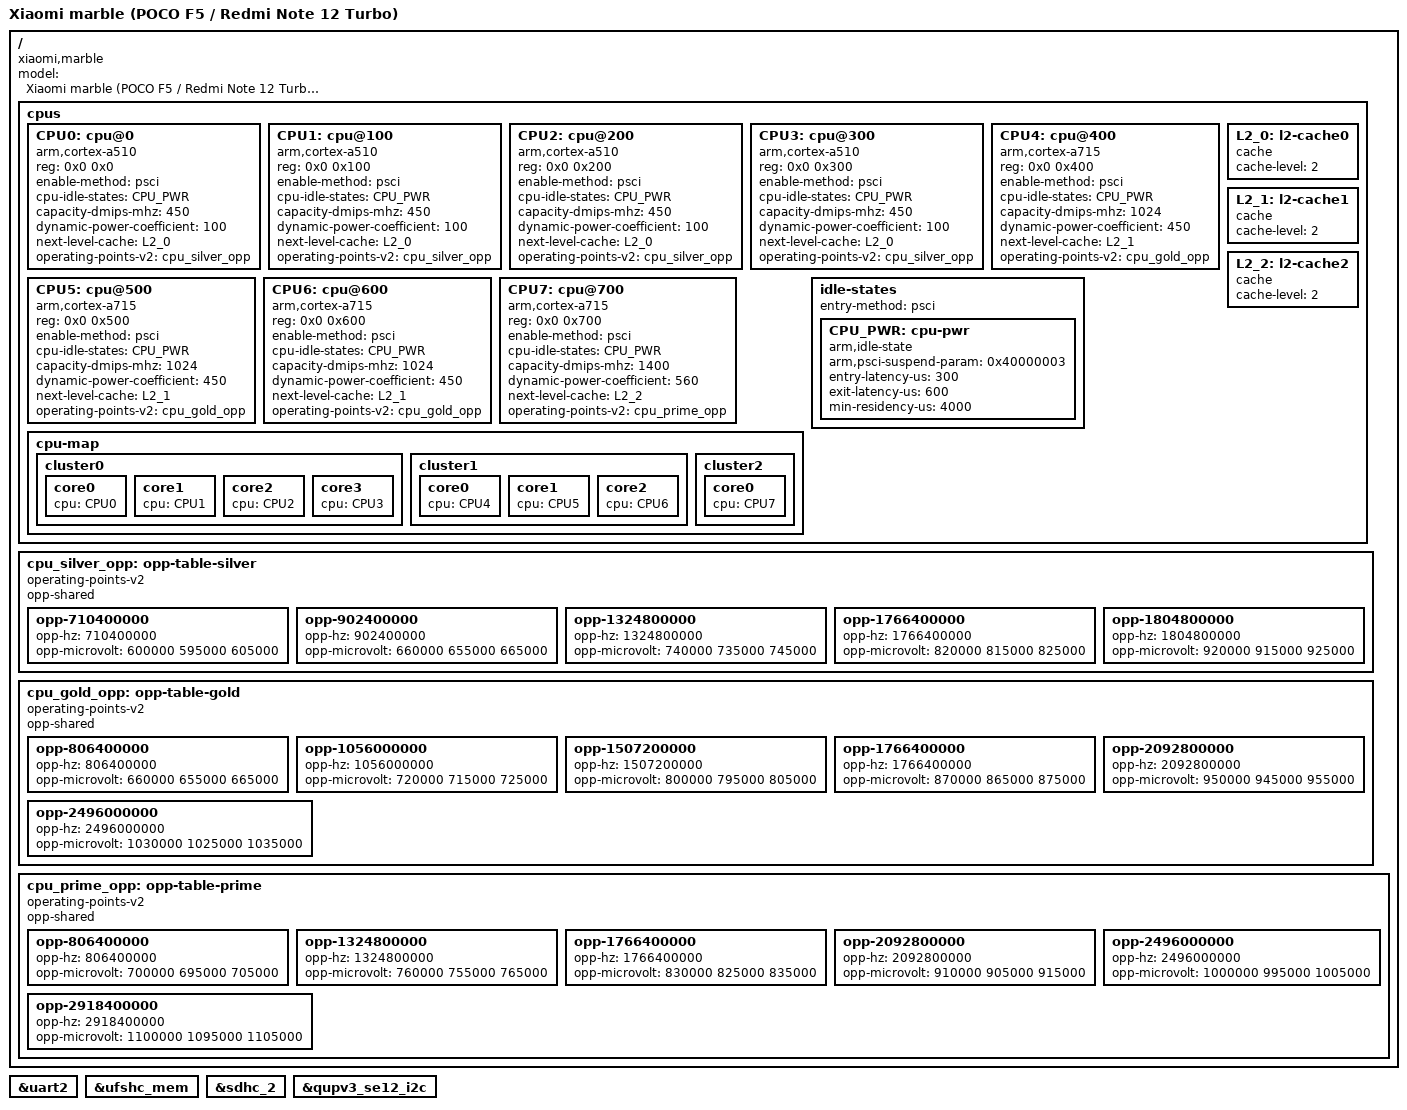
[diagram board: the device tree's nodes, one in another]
// SPDX-License-Identifier: GPL-2.0-only
/*
 * marble-board.dts
 *
 * Top-level board file for Xiaomi marble (POCO F5 / Redmi Note 12 Turbo).
 * Platform: SM8450 (waipio/taro) base, SM7475 (diwali) die.
 *
 * The kernel builds with CONFIG_ARCH_WAIPIO=y and diwali clock overrides.
 * The defconfig chain is: gki_defconfig + waipio_GKI.config +
 * xiaomi_GKI.config + marble_GKI.config.
 *
 * Aurora-Kernel  ::  ACK 6.18 LTS
 */

/dts-v1/;

#include "waipio.dtsi"
#include "sm7475-marble.dtsi"
#include "marble-peripherals.dtsi"

/ {
    model = "Xiaomi marble (POCO F5 / Redmi Note 12 Turbo)";
    compatible = "xiaomi,marble", "qcom,waipio", "qcom,diwali";

    /*
     * CPU cluster topology for EAS.
     * SM7475 = 1x Cortex-A715 prime @ 2.91GHz
     *        + 3x Cortex-A715 gold  @ 2.49GHz
     *        + 4x Cortex-A510 silver @ 1.80GHz
     */
    cpus {
        #address-cells = <2>;
        #size-cells = <0>;

        CPU0: cpu@0 {
            device_type = "cpu";
            compatible = "arm,cortex-a510";
            reg = <0x0 0x0>;
            enable-method = "psci";
            cpu-idle-states = <&CPU_PWR>;
            capacity-dmips-mhz = <450>;
            dynamic-power-coefficient = <100>;
            next-level-cache = <&L2_0>;
            operating-points-v2 = <&cpu_silver_opp>;
            #cooling-cells = <2>;
        };

        CPU1: cpu@100 {
            device_type = "cpu";
            compatible = "arm,cortex-a510";
            reg = <0x0 0x100>;
            enable-method = "psci";
            cpu-idle-states = <&CPU_PWR>;
            capacity-dmips-mhz = <450>;
            dynamic-power-coefficient = <100>;
            next-level-cache = <&L2_0>;
            operating-points-v2 = <&cpu_silver_opp>;
        };

        CPU2: cpu@200 {
            device_type = "cpu";
            compatible = "arm,cortex-a510";
            reg = <0x0 0x200>;
            enable-method = "psci";
            cpu-idle-states = <&CPU_PWR>;
            capacity-dmips-mhz = <450>;
            dynamic-power-coefficient = <100>;
            next-level-cache = <&L2_0>;
            operating-points-v2 = <&cpu_silver_opp>;
        };

        CPU3: cpu@300 {
            device_type = "cpu";
            compatible = "arm,cortex-a510";
            reg = <0x0 0x300>;
            enable-method = "psci";
            cpu-idle-states = <&CPU_PWR>;
            capacity-dmips-mhz = <450>;
            dynamic-power-coefficient = <100>;
            next-level-cache = <&L2_0>;
            operating-points-v2 = <&cpu_silver_opp>;
        };

        CPU4: cpu@400 {
            device_type = "cpu";
            compatible = "arm,cortex-a715";
            reg = <0x0 0x400>;
            enable-method = "psci";
            cpu-idle-states = <&CPU_PWR>;
            capacity-dmips-mhz = <1024>;
            dynamic-power-coefficient = <450>;
            next-level-cache = <&L2_1>;
            operating-points-v2 = <&cpu_gold_opp>;
            #cooling-cells = <2>;
        };

        CPU5: cpu@500 {
            device_type = "cpu";
            compatible = "arm,cortex-a715";
            reg = <0x0 0x500>;
            enable-method = "psci";
            cpu-idle-states = <&CPU_PWR>;
            capacity-dmips-mhz = <1024>;
            dynamic-power-coefficient = <450>;
            next-level-cache = <&L2_1>;
            operating-points-v2 = <&cpu_gold_opp>;
        };

        CPU6: cpu@600 {
            device_type = "cpu";
            compatible = "arm,cortex-a715";
            reg = <0x0 0x600>;
            enable-method = "psci";
            cpu-idle-states = <&CPU_PWR>;
            capacity-dmips-mhz = <1024>;
            dynamic-power-coefficient = <450>;
            next-level-cache = <&L2_1>;
            operating-points-v2 = <&cpu_gold_opp>;
        };

        CPU7: cpu@700 {
            device_type = "cpu";
            compatible = "arm,cortex-a715";
            reg = <0x0 0x700>;
            enable-method = "psci";
            cpu-idle-states = <&CPU_PWR>;
            capacity-dmips-mhz = <1400>;
            dynamic-power-coefficient = <560>;
            next-level-cache = <&L2_2>;
            operating-points-v2 = <&cpu_prime_opp>;
            #cooling-cells = <2>;
        };

        /* cluster topology for EAS */
        cpu-map {
            cluster0 {
                core0 { cpu = <&CPU0>; };
                core1 { cpu = <&CPU1>; };
                core2 { cpu = <&CPU2>; };
                core3 { cpu = <&CPU3>; };
            };
            cluster1 {
                core0 { cpu = <&CPU4>; };
                core1 { cpu = <&CPU5>; };
                core2 { cpu = <&CPU6>; };
            };
            cluster2 {
                core0 { cpu = <&CPU7>; };
            };
        };

        idle-states {
            entry-method = "psci";
            CPU_PWR: cpu-pwr {
                compatible = "arm,idle-state";
                arm,psci-suspend-param = <0x40000003>;
                entry-latency-us = <300>;
                exit-latency-us = <600>;
                min-residency-us = <4000>;
            };
        };

        L2_0: l2-cache0 { compatible = "cache"; cache-level = <2>; };
        L2_1: l2-cache1 { compatible = "cache"; cache-level = <2>; };
        L2_2: l2-cache2 { compatible = "cache"; cache-level = <2>; };
    };

    /*
     * OPP tables with Undervolting (UV).
     *
     * UV is achieved via `opp-microvolt = <target min max>`.
     * Values below are conservative (≈ -25mV below stock SM7475).
     * Every device's silicon is different — if you get crashes at high
     * freq, RAISE the target voltage by 10mV increments until stable.
     *
     * Format: opp-microvolt = <target_uv  min_uv  max_uv>;
     *   target_uv = the voltage to actually apply (this is the UV)
     *   min/max   = the regulator tolerance window (keep ±5mV)
     *
     * Stock SM7475 reference voltages (Qualcomm LA.VENDOR.1.0):
     *   silver  : 0.60 - 0.95 V
     *   gold    : 0.65 - 1.05 V
     *   prime   : 0.70 - 1.12 V
     */
    cpu_silver_opp: opp-table-silver {
        compatible = "operating-points-v2";
        opp-shared;

        opp-710400000  { opp-hz = /bits/ 64 <710400000>;
                         opp-microvolt = <600000 595000 605000>; };
        opp-902400000  { opp-hz = /bits/ 64 <902400000>;
                         opp-microvolt = <660000 655000 665000>; };
        opp-1324800000 { opp-hz = /bits/ 64 <1324800000>;
                         opp-microvolt = <740000 735000 745000>; };
        opp-1766400000 { opp-hz = /bits/ 64 <1766400000>;
                         opp-microvolt = <820000 815000 825000>; };
        opp-1804800000 { opp-hz = /bits/ 64 <1804800000>;
                         opp-microvolt = <920000 915000 925000>; };
    };

    cpu_gold_opp: opp-table-gold {
        compatible = "operating-points-v2";
        opp-shared;

        opp-806400000  { opp-hz = /bits/ 64 <806400000>;
                         opp-microvolt = <660000 655000 665000>; };
        opp-1056000000 { opp-hz = /bits/ 64 <1056000000>;
                         opp-microvolt = <720000 715000 725000>; };
        opp-1507200000 { opp-hz = /bits/ 64 <1507200000>;
                         opp-microvolt = <800000 795000 805000>; };
        opp-1766400000 { opp-hz = /bits/ 64 <1766400000>;
                         opp-microvolt = <870000 865000 875000>; };
        opp-2092800000 { opp-hz = /bits/ 64 <2092800000>;
                         opp-microvolt = <950000 945000 955000>; };
        opp-2496000000 { opp-hz = /bits/ 64 <2496000000>;
                         opp-microvolt = <1030000 1025000 1035000>; };
    };

    cpu_prime_opp: opp-table-prime {
        compatible = "operating-points-v2";
        opp-shared;

        opp-806400000  { opp-hz = /bits/ 64 <806400000>;
                         opp-microvolt = <700000 695000 705000>; };
        opp-1324800000 { opp-hz = /bits/ 64 <1324800000>;
                         opp-microvolt = <760000 755000 765000>; };
        opp-1766400000 { opp-hz = /bits/ 64 <1766400000>;
                         opp-microvolt = <830000 825000 835000>; };
        opp-2092800000 { opp-hz = /bits/ 64 <2092800000>;
                         opp-microvolt = <910000 905000 915000>; };
        opp-2496000000 { opp-hz = /bits/ 64 <2496000000>;
                         opp-microvolt = <1000000 995000 1005000>; };
        opp-2918400000 { opp-hz = /bits/ 64 <2918400000>;
                         opp-microvolt = <1100000 1095000 1105000>; };
    };
};

/* enable the SoC nodes that marble board uses */
&uart2 { status = "okay"; };     // debug console
&ufshc_mem { status = "okay"; }; // UFS storage
&sdhc_2 { status = "okay"; };    // microSD slot
&qupv3_se12_i2c { status = "okay"; }; // touchscreen / fuel gauge bus
